AUTOSAR XML (schema 4.0)
package /Interfaces
  sender receiver interface If_EngineSpeed
    data EngineSpeed: type=uint16, init-value=0
  sender receiver interface If_VehicleSpeed
    data VehicleSpeed: type=float32
  client server interface If_DiagService
    operation GetStatus
      arg status: type=uint8, direction=OUT
package /Components
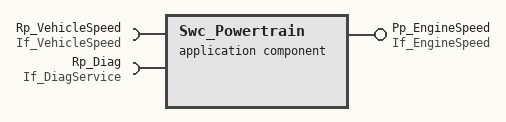
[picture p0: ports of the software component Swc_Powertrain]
  application sw component type Swc_Powertrain
    provide port Pp_EngineSpeed: provided-interface=If_EngineSpeed
    require port Rp_VehicleSpeed: required-interface=If_VehicleSpeed
    require port Rp_Diag: required-interface=If_DiagService
